AUTOSAR XML (schema 4-3-0)
package /CAN3/ISignalGroup
  17 x i signal group:
    CAN3_SG_B2TM_Info: i-signal=[CAN3_B2TChgSta, CAN3_B2THVCmd, CAN3_B2THVRlySta, CAN3_B2TMCRC, CAN3_B2TMLifeSig, CAN3_B2TPackVol, CAN3_B2TSetModeA, CAN3_B2TSetTemp], system-signal-group=CAN3_SG_B2TM_Info
    CAN3_SG_B2V_BattInfo1: i-signal=[CAN3_B2VBI1BattType, CAN3_B2VBI1RateCap, CAN3_B2VBI1RateHVolt, CAN3_B2VBI1RatePower], system-signal-group=CAN3_SG_B2V_BattInfo1
    CAN3_SG_B2V_CurrentLimit: i-signal=[CAN3_B2VAPlsDischgCurr, CAN3_B2VAvaPlsChgCurr], system-signal-group=CAN3_SG_B2V_CurrentLimit
    CAN3_SG_B2V_Fult1_32960: i-signal=CAN3_B2VHVILFault, system-signal-group=CAN3_SG_B2V_Fult1_32960
    CAN3_SG_B2V_ST1: i-signal=[CAN3_B2VACChgConnSta, CAN3_B2VACChgNegRlySta, CAN3_B2VACChgPosRlySta, CAN3_B2VAux1RlySta, CAN3_B2VAux2RlySta, CAN3_B2VAux3RlySta, CAN3_B2VBMUBalSta, CAN3_B2VBMUHVSta, CAN3_B2VChgMode, CAN3_B2VChgSta, CAN3_B2VCoolingSta, CAN3_B2VDCChgConnSta, CAN3_B2VDCChgN1RlySta, CAN3_B2VDCChgN2RlySta, CAN3_B2VDCChgP1RlySta, CAN3_B2VDCChgP2RlySta, CAN3_B2VHeatNegRelaySta, CAN3_B2VHeatPosRlySta, CAN3_B2VHeatingSta, CAN3_B2VMainNegRlySta, CAN3_B2VMainPosRlySta, CAN3_B2VPChgPosRlySta, CAN3_B2VPChrgConnSta, CAN3_B2VPChrgNegRlySta, CAN3_B2VPrechgRelaySta, CAN3_B2VST1RChrgCy], system-signal-group=CAN3_SG_B2V_ST1
    CAN3_SG_B2V_ST2: i-signal=[CAN3_B2VFaultCode, CAN3_B2VFaultLv, CAN3_B2VPackCurr, CAN3_B2VPackInsideVol, CAN3_B2VRqHVPwrOff, CAN3_B2VSOC, CAN3_B2VSOH, CAN3_B2VST2LifeSig], system-signal-group=CAN3_SG_B2V_ST2
    CAN3_SG_B2V_ST4: i-signal=[CAN3_B2VCellAvgTemp, CAN3_B2VMaxTempCSCSN, CAN3_B2VMaxTempPos, CAN3_B2VMinTempCSCSN, CAN3_B2VMinTempPos, CAN3_B2VPackMaxTemp, CAN3_B2VPackMinTemp], system-signal-group=CAN3_SG_B2V_ST4
    CAN3_SG_B2V_ST5: i-signal=CAN3_B2VCellMinVol, system-signal-group=CAN3_SG_B2V_ST5
    CAN3_SG_EWP1: i-signal=CAN3_EWPPEFault, system-signal-group=CAN3_SG_EWP1
    CAN3_SG_FD3_C100_0: i-signal=[CAN3_V2BACPosRlyFlt, CAN3_V2BACPosRlySta, CAN3_V2BAirPosRlyFlt, CAN3_V2BAirPosRlySta, CAN3_V2BAux1OnOff, CAN3_V2BAux1RlyFlt, CAN3_V2BAux1RlySta, CAN3_V2BAux2OnOff, CAN3_V2BAux2RlyFlt, CAN3_V2BAux2RlySta, CAN3_V2BAux3OnOff, CAN3_V2BAux3RlyFlt, CAN3_V2BAux3RlySta, CAN3_V2BAux4ReyFlt, CAN3_V2BAux4RlySta, CAN3_V2BDCDCPosRlyFlt, CAN3_V2BDCDCPosRlySta, CAN3_V2BHVOnOff, CAN3_V2BLifeSig, CAN3_V2BMainPosRlyFlt, CAN3_V2BMainPosRlySta, CAN3_V2BOilPosRlyFlt, CAN3_V2BOilPosRlySta, CAN3_V2BVehSpd], system-signal-group=CAN3_SG_FD3_C100_0
    CAN3_SG_FD3_C10_0: i-signal=[CAN3_DCDCRlyEn, CAN3_EACRlyEn, CAN3_EHPSRlyEn, CAN3_MCUHVPwrOnOffReq, CAN3_VCULife1], system-signal-group=CAN3_SG_FD3_C10_0
    CAN3_SG_FD3_C10_1: i-signal=[CAN3_VCUMCUCtrlMd, CAN3_VCUMCUDemCS, CAN3_VCUMCUDemHiPosVal, CAN3_VCUMCUDemLoNegVal, CAN3_VCUMCUDemRC, CAN3_VCUMCUDemSpd, CAN3_VCUMCUDemTrq, CAN3_VCUMCUEn, CAN3_VCUMCUFailRst, CAN3_VCUMCUFootBrk, CAN3_VCUMCUGearSta, CAN3_VCUMCUHandBrk], system-signal-group=CAN3_SG_FD3_C10_1
    CAN3_SG_FD3_C200_0: i-signal=[CAN3_ChrgFault, CAN3_ChrgState, CAN3_PowerDownFault, CAN3_PowerDownState, CAN3_PowerUpFault, CAN3_PowerUpState, CAN3_SysPowerMode, CAN3_VCUIGNSta, CAN3_VCUIRCSta, CAN3_VCUPSSSta], system-signal-group=CAN3_SG_FD3_C200_0
    CAN3_SG_FD3_C200_1: i-signal=CAN3_FDC_THCM_EWPPEReq_Cmd, system-signal-group=CAN3_SG_FD3_C200_1
    CAN3_SG_TM_MCUSta1: i-signal=[CAN3_AtvDisChgEnFbk, CAN3_MCUCtrlMdSta, CAN3_MCUIGBTEnFbk, CAN3_MCUMsgSta1LCnt, CAN3_MotorSpd, CAN3_MotorTrq], system-signal-group=CAN3_SG_TM_MCUSta1
    CAN3_SG_TM_MCUSta2: i-signal=[CAN3_MCUFailGrade, CAN3_MCUMsgSta2LCnt, CAN3_MCUTemp, CAN3_MCUTrqLimHi, CAN3_MCUTrqLimLo, CAN3_MotorTemp], system-signal-group=CAN3_SG_TM_MCUSta2
    CAN3_SG_TM_MCUSta3: i-signal=[CAN3_MCUDCCur, CAN3_MCUDCVol, CAN3_MCUFailCode], system-signal-group=CAN3_SG_TM_MCUSta3
package /CAN3/Cluster
  can cluster CAN3: baudrate=500
    can physical channel CAN3: comm-connectors=ConnCAN3
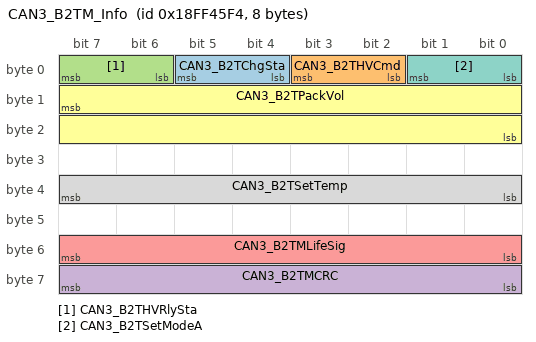
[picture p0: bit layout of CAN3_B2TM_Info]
      frame CAN3_B2TM_Info: id 0x18FF45F4, frame-length=8, can-addressing-mode=EXTENDED, can-fd-frame-support=false, can-frame-rx-behavior=CAN-20, can-frame-tx-behavior=CAN-20
        pdu CAN3_B2TM_Info: length=8, minimum-delay=0.0, transmission-mode-true-timing=cyclic-timing=time-period=1, unused-bit-pattern=0
          mapping CAN3_SG_B2TM_Info: i-signal-group=CAN3_SG_B2TM_Info, start-position=0, transfer-property=PENDING
          signal CAN3_B2TChgSta: start 5, 2 bit, big-endian, i-signal-type=PRIMITIVE, init-value=constant-reference=Init_CAN3_B2TChgSta, base-type=uint8, implementation-data-type=uint8, transfer-property=PENDING
          signal CAN3_B2THVCmd: start 3, 2 bit, big-endian, i-signal-type=PRIMITIVE, init-value=constant-reference=Init_CAN3_B2THVCmd, base-type=uint8, implementation-data-type=uint8, transfer-property=PENDING
          signal CAN3_B2THVRlySta: start 7, 2 bit, big-endian, i-signal-type=PRIMITIVE, init-value=constant-reference=Init_CAN3_B2THVRlySta, base-type=uint8, implementation-data-type=uint8, transfer-property=PENDING
          signal CAN3_B2TMCRC: start 63, 8 bit, big-endian, i-signal-type=PRIMITIVE, init-value=constant-reference=Init_CAN3_B2TMCRC, base-type=uint8, implementation-data-type=uint8, transfer-property=PENDING
          signal CAN3_B2TMLifeSig: start 55, 8 bit, big-endian, i-signal-type=PRIMITIVE, init-value=constant-reference=Init_CAN3_B2TMLifeSig, base-type=uint8, implementation-data-type=uint8, transfer-property=PENDING
          signal CAN3_B2TPackVol: start 15, 16 bit, big-endian, i-signal-type=PRIMITIVE, init-value=constant-reference=Init_CAN3_B2TPackVol, base-type=uint16, implementation-data-type=uint16, transfer-property=PENDING
          signal CAN3_B2TSetModeA: start 1, 2 bit, big-endian, i-signal-type=PRIMITIVE, init-value=constant-reference=Init_CAN3_B2TSetModeA, base-type=uint8, implementation-data-type=uint8, transfer-property=PENDING
          signal CAN3_B2TSetTemp: start 39, 8 bit, big-endian, i-signal-type=PRIMITIVE, init-value=constant-reference=Init_CAN3_B2TSetTemp, base-type=uint8, implementation-data-type=uint8, transfer-property=PENDING
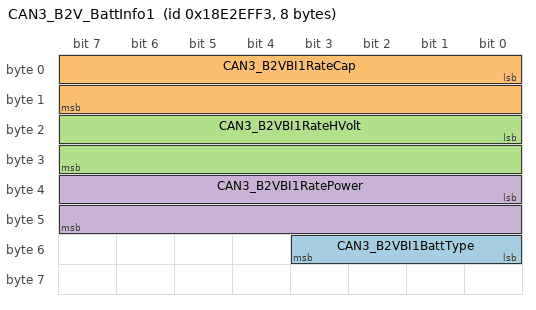
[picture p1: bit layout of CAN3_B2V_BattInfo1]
      frame CAN3_B2V_BattInfo1: id 0x18E2EFF3, frame-length=8, can-addressing-mode=EXTENDED, can-fd-frame-support=false, can-frame-rx-behavior=CAN-20, can-frame-tx-behavior=CAN-20
        pdu CAN3_B2V_BattInfo1: length=8, minimum-delay=0.0, transmission-mode-true-timing=cyclic-timing=time-period=1, unused-bit-pattern=0
          mapping CAN3_SG_B2V_BattInfo1: i-signal-group=CAN3_SG_B2V_BattInfo1, start-position=0, transfer-property=PENDING
          signal CAN3_B2VBI1BattType: start 48, 4 bit, little-endian, i-signal-type=PRIMITIVE, init-value=constant-reference=Init_CAN3_B2VBI1BattType, base-type=uint8, implementation-data-type=uint8, transfer-property=PENDING
          signal CAN3_B2VBI1RateCap: start 0, 16 bit, little-endian, i-signal-type=PRIMITIVE, init-value=constant-reference=Init_CAN3_B2VBI1RateCap, base-type=uint16, implementation-data-type=uint16, transfer-property=PENDING
          signal CAN3_B2VBI1RateHVolt: start 16, 16 bit, little-endian, i-signal-type=PRIMITIVE, init-value=constant-reference=Init_CAN3_B2VBI1RateHVolt, base-type=uint16, implementation-data-type=uint16, transfer-property=PENDING
          signal CAN3_B2VBI1RatePower: start 32, 16 bit, little-endian, i-signal-type=PRIMITIVE, init-value=constant-reference=Init_CAN3_B2VBI1RatePower, base-type=uint16, implementation-data-type=uint16, transfer-property=PENDING
      frame CAN3_B2V_CurrentLimit: id 0x18C4EFF3, frame-length=8, can-addressing-mode=EXTENDED, can-fd-frame-support=false, can-frame-rx-behavior=CAN-20, can-frame-tx-behavior=CAN-20
        pdu CAN3_B2V_CurrentLimit: length=8, minimum-delay=0.0, transmission-mode-true-timing=cyclic-timing=time-period=0.2, unused-bit-pattern=0
          mapping CAN3_SG_B2V_CurrentLimit: i-signal-group=CAN3_SG_B2V_CurrentLimit, start-position=0, transfer-property=PENDING
          signal CAN3_B2VAPlsDischgCurr: start 0, 16 bit, little-endian, i-signal-type=PRIMITIVE, init-value=constant-reference=Init_CAN3_B2VAPlsDischgCurr, base-type=uint16, implementation-data-type=uint16, transfer-property=PENDING
          signal CAN3_B2VAvaPlsChgCurr: start 16, 16 bit, little-endian, i-signal-type=PRIMITIVE, init-value=constant-reference=Init_CAN3_B2VAvaPlsChgCurr, base-type=uint16, implementation-data-type=uint16, transfer-property=PENDING
      frame CAN3_B2V_Fult1_32960: id 0x1881EFF3, frame-length=8, can-addressing-mode=EXTENDED, can-fd-frame-support=false, can-frame-rx-behavior=CAN-20, can-frame-tx-behavior=CAN-20
        pdu CAN3_B2V_Fult1_32960: length=8, minimum-delay=0.0, transmission-mode-true-timing=cyclic-timing=time-period=0.5, unused-bit-pattern=0
          mapping CAN3_SG_B2V_Fult1_32960: i-signal-group=CAN3_SG_B2V_Fult1_32960, start-position=0, transfer-property=PENDING
          signal CAN3_B2VHVILFault: start 26, 1 bit, little-endian, i-signal-type=PRIMITIVE, init-value=constant-reference=Init_CAN3_B2VHVILFault, base-type=uint8, implementation-data-type=uint8, transfer-property=PENDING
      frame CAN3_B2V_ST1: id 0x1883EFF3, frame-length=8, can-addressing-mode=EXTENDED, can-fd-frame-support=false, can-frame-rx-behavior=CAN-20, can-frame-tx-behavior=CAN-20
        pdu CAN3_B2V_ST1: length=8, minimum-delay=0.0, transmission-mode-true-timing=cyclic-timing=time-period=0.1, unused-bit-pattern=0
          mapping CAN3_SG_B2V_ST1: i-signal-group=CAN3_SG_B2V_ST1, start-position=0, transfer-property=PENDING
          signal CAN3_B2VACChgConnSta: start 38, 1 bit, little-endian, i-signal-type=PRIMITIVE, init-value=constant-reference=Init_CAN3_B2VACChgConnSta, base-type=uint8, implementation-data-type=uint8, transfer-property=PENDING
          signal CAN3_B2VACChgNegRlySta: start 24, 2 bit, little-endian, i-signal-type=PRIMITIVE, init-value=constant-reference=Init_CAN3_B2VACChgNegRlySta, base-type=uint8, implementation-data-type=uint8, transfer-property=PENDING
          signal CAN3_B2VACChgPosRlySta: start 22, 2 bit, little-endian, i-signal-type=PRIMITIVE, init-value=constant-reference=Init_CAN3_B2VACChgPosRlySta, base-type=uint8, implementation-data-type=uint8, transfer-property=PENDING
          signal CAN3_B2VAux1RlySta: start 26, 2 bit, little-endian, i-signal-type=PRIMITIVE, init-value=constant-reference=Init_CAN3_B2VAux1RlySta, base-type=uint8, implementation-data-type=uint8, transfer-property=PENDING
          signal CAN3_B2VAux2RlySta: start 28, 2 bit, little-endian, i-signal-type=PRIMITIVE, init-value=constant-reference=Init_CAN3_B2VAux2RlySta, base-type=uint8, implementation-data-type=uint8, transfer-property=PENDING
          signal CAN3_B2VAux3RlySta: start 30, 2 bit, little-endian, i-signal-type=PRIMITIVE, init-value=constant-reference=Init_CAN3_B2VAux3RlySta, base-type=uint8, implementation-data-type=uint8, transfer-property=PENDING
          signal CAN3_B2VBMUBalSta: start 34, 1 bit, little-endian, i-signal-type=PRIMITIVE, init-value=constant-reference=Init_CAN3_B2VBMUBalSta, base-type=uint8, implementation-data-type=uint8, transfer-property=PENDING
          signal CAN3_B2VBMUHVSta: start 32, 2 bit, little-endian, i-signal-type=PRIMITIVE, init-value=constant-reference=Init_CAN3_B2VBMUHVSta, base-type=uint8, implementation-data-type=uint8, transfer-property=PENDING
          signal CAN3_B2VChgMode: start 39, 2 bit, little-endian, i-signal-type=PRIMITIVE, init-value=constant-reference=Init_CAN3_B2VChgMode, base-type=uint8, implementation-data-type=uint8, transfer-property=PENDING
          signal CAN3_B2VChgSta: start 41, 2 bit, little-endian, i-signal-type=PRIMITIVE, init-value=constant-reference=Init_CAN3_B2VChgSta, base-type=uint8, implementation-data-type=uint8, transfer-property=PENDING
          signal CAN3_B2VCoolingSta: start 44, 2 bit, little-endian, i-signal-type=PRIMITIVE, init-value=constant-reference=Init_CAN3_B2VCoolingSta, base-type=uint8, implementation-data-type=uint8, transfer-property=PENDING
          signal CAN3_B2VDCChgConnSta: start 35, 2 bit, little-endian, i-signal-type=PRIMITIVE, init-value=constant-reference=Init_CAN3_B2VDCChgConnSta, base-type=uint8, implementation-data-type=uint8, transfer-property=PENDING
          signal CAN3_B2VDCChgN1RlySta: start 8, 2 bit, little-endian, i-signal-type=PRIMITIVE, init-value=constant-reference=Init_CAN3_B2VDCChgN1RlySta, base-type=uint8, implementation-data-type=uint8, transfer-property=PENDING
          signal CAN3_B2VDCChgN2RlySta: start 12, 2 bit, little-endian, i-signal-type=PRIMITIVE, init-value=constant-reference=Init_CAN3_B2VDCChgN2RlySta, base-type=uint8, implementation-data-type=uint8, transfer-property=PENDING
          signal CAN3_B2VDCChgP1RlySta: start 6, 2 bit, little-endian, i-signal-type=PRIMITIVE, init-value=constant-reference=Init_CAN3_B2VDCChgP1RlySta, base-type=uint8, implementation-data-type=uint8, transfer-property=PENDING
          signal CAN3_B2VDCChgP2RlySta: start 10, 2 bit, little-endian, i-signal-type=PRIMITIVE, init-value=constant-reference=Init_CAN3_B2VDCChgP2RlySta, base-type=uint8, implementation-data-type=uint8, transfer-property=PENDING
          signal CAN3_B2VHeatNegRelaySta: start 16, 2 bit, little-endian, i-signal-type=PRIMITIVE, init-value=constant-reference=Init_CAN3_B2VHeatNegRelaySta, base-type=uint8, implementation-data-type=uint8, transfer-property=PENDING
          signal CAN3_B2VHeatPosRlySta: start 14, 2 bit, little-endian, i-signal-type=PRIMITIVE, init-value=constant-reference=Init_CAN3_B2VHeatPosRlySta, base-type=uint8, implementation-data-type=uint8, transfer-property=PENDING
          signal CAN3_B2VHeatingSta: start 43, 1 bit, little-endian, i-signal-type=PRIMITIVE, init-value=constant-reference=Init_CAN3_B2VHeatingSta, base-type=uint8, implementation-data-type=uint8, transfer-property=PENDING
          signal CAN3_B2VMainNegRlySta: start 2, 2 bit, little-endian, i-signal-type=PRIMITIVE, init-value=constant-reference=Init_CAN3_B2VMainNegRlySta, base-type=uint8, implementation-data-type=uint8, transfer-property=PENDING
          signal CAN3_B2VMainPosRlySta: start 0, 2 bit, little-endian, i-signal-type=PRIMITIVE, init-value=constant-reference=Init_CAN3_B2VMainPosRlySta, base-type=uint8, implementation-data-type=uint8, transfer-property=PENDING
          signal CAN3_B2VPChgPosRlySta: start 18, 2 bit, little-endian, i-signal-type=PRIMITIVE, init-value=constant-reference=Init_CAN3_B2VPChgPosRlySta, base-type=uint8, implementation-data-type=uint8, transfer-property=PENDING
          signal CAN3_B2VPChrgConnSta: start 37, 1 bit, little-endian, i-signal-type=PRIMITIVE, init-value=constant-reference=Init_CAN3_B2VPChrgConnSta, base-type=uint8, implementation-data-type=uint8, transfer-property=PENDING
          signal CAN3_B2VPChrgNegRlySta: start 20, 2 bit, little-endian, i-signal-type=PRIMITIVE, init-value=constant-reference=Init_CAN3_B2VPChrgNegRlySta, base-type=uint8, implementation-data-type=uint8, transfer-property=PENDING
          signal CAN3_B2VPrechgRelaySta: start 4, 2 bit, little-endian, i-signal-type=PRIMITIVE, init-value=constant-reference=Init_CAN3_B2VPrechgRelaySta, base-type=uint8, implementation-data-type=uint8, transfer-property=PENDING
          signal CAN3_B2VST1RChrgCy: start 46, 18 bit, little-endian, i-signal-type=PRIMITIVE, init-value=constant-reference=Init_CAN3_B2VST1RChrgCy, base-type=uint32, implementation-data-type=uint32, transfer-property=PENDING
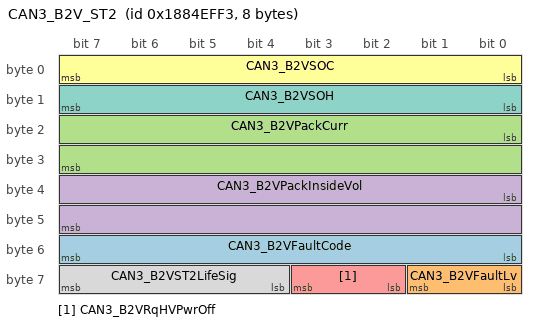
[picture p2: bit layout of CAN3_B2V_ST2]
      frame CAN3_B2V_ST2: id 0x1884EFF3, frame-length=8, can-addressing-mode=EXTENDED, can-fd-frame-support=false, can-frame-rx-behavior=CAN-20, can-frame-tx-behavior=CAN-20
        pdu CAN3_B2V_ST2: length=8, minimum-delay=0.0, transmission-mode-true-timing=cyclic-timing=time-period=0.2, unused-bit-pattern=0
          mapping CAN3_SG_B2V_ST2: i-signal-group=CAN3_SG_B2V_ST2, start-position=0, transfer-property=PENDING
          signal CAN3_B2VFaultCode: start 48, 8 bit, little-endian, i-signal-type=PRIMITIVE, init-value=constant-reference=Init_CAN3_B2VFaultCode, base-type=uint8, implementation-data-type=uint8, transfer-property=PENDING
          signal CAN3_B2VFaultLv: start 56, 2 bit, little-endian, i-signal-type=PRIMITIVE, init-value=constant-reference=Init_CAN3_B2VFaultLv, base-type=uint8, implementation-data-type=uint8, transfer-property=PENDING
          signal CAN3_B2VPackCurr: start 16, 16 bit, little-endian, i-signal-type=PRIMITIVE, init-value=constant-reference=Init_CAN3_B2VPackCurr, base-type=uint16, implementation-data-type=uint16, transfer-property=PENDING
          signal CAN3_B2VPackInsideVol: start 32, 16 bit, little-endian, i-signal-type=PRIMITIVE, init-value=constant-reference=Init_CAN3_B2VPackInsideVol, base-type=uint16, implementation-data-type=uint16, transfer-property=PENDING
          signal CAN3_B2VRqHVPwrOff: start 58, 2 bit, little-endian, i-signal-type=PRIMITIVE, init-value=constant-reference=Init_CAN3_B2VRqHVPwrOff, base-type=uint8, implementation-data-type=uint8, transfer-property=PENDING
          signal CAN3_B2VSOC: start 0, 8 bit, little-endian, i-signal-type=PRIMITIVE, init-value=constant-reference=Init_CAN3_B2VSOC, base-type=uint8, implementation-data-type=uint8, transfer-property=PENDING
          signal CAN3_B2VSOH: start 8, 8 bit, little-endian, i-signal-type=PRIMITIVE, init-value=constant-reference=Init_CAN3_B2VSOH, base-type=uint8, implementation-data-type=uint8, transfer-property=PENDING
          signal CAN3_B2VST2LifeSig: start 60, 4 bit, little-endian, i-signal-type=PRIMITIVE, init-value=constant-reference=Init_CAN3_B2VST2LifeSig, base-type=uint8, implementation-data-type=uint8, transfer-property=PENDING
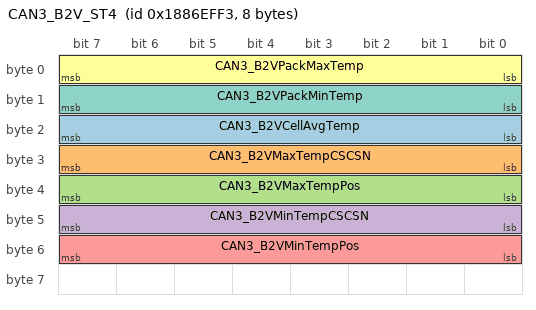
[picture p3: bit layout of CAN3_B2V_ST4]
      frame CAN3_B2V_ST4: id 0x1886EFF3, frame-length=8, can-addressing-mode=EXTENDED, can-fd-frame-support=false, can-frame-rx-behavior=CAN-20, can-frame-tx-behavior=CAN-20
        pdu CAN3_B2V_ST4: length=8, minimum-delay=0.0, transmission-mode-true-timing=cyclic-timing=time-period=0.5, unused-bit-pattern=0
          mapping CAN3_SG_B2V_ST4: i-signal-group=CAN3_SG_B2V_ST4, start-position=0, transfer-property=PENDING
          signal CAN3_B2VCellAvgTemp: start 16, 8 bit, little-endian, i-signal-type=PRIMITIVE, init-value=constant-reference=Init_CAN3_B2VCellAvgTemp, base-type=uint8, implementation-data-type=uint8, transfer-property=PENDING
          signal CAN3_B2VMaxTempCSCSN: start 24, 8 bit, little-endian, i-signal-type=PRIMITIVE, init-value=constant-reference=Init_CAN3_B2VMaxTempCSCSN, base-type=uint8, implementation-data-type=uint8, transfer-property=PENDING
          signal CAN3_B2VMaxTempPos: start 32, 8 bit, little-endian, i-signal-type=PRIMITIVE, init-value=constant-reference=Init_CAN3_B2VMaxTempPos, base-type=uint8, implementation-data-type=uint8, transfer-property=PENDING
          signal CAN3_B2VMinTempCSCSN: start 40, 8 bit, little-endian, i-signal-type=PRIMITIVE, init-value=constant-reference=Init_CAN3_B2VMinTempCSCSN, base-type=uint8, implementation-data-type=uint8, transfer-property=PENDING
          signal CAN3_B2VMinTempPos: start 48, 8 bit, little-endian, i-signal-type=PRIMITIVE, init-value=constant-reference=Init_CAN3_B2VMinTempPos, base-type=uint8, implementation-data-type=uint8, transfer-property=PENDING
          signal CAN3_B2VPackMaxTemp: start 0, 8 bit, little-endian, i-signal-type=PRIMITIVE, init-value=constant-reference=Init_CAN3_B2VPackMaxTemp, base-type=uint8, implementation-data-type=uint8, transfer-property=PENDING
          signal CAN3_B2VPackMinTemp: start 8, 8 bit, little-endian, i-signal-type=PRIMITIVE, init-value=constant-reference=Init_CAN3_B2VPackMinTemp, base-type=uint8, implementation-data-type=uint8, transfer-property=PENDING
      frame CAN3_B2V_ST5: id 0x1887EFF3, frame-length=8, can-addressing-mode=EXTENDED, can-fd-frame-support=false, can-frame-rx-behavior=CAN-20, can-frame-tx-behavior=CAN-20
        pdu CAN3_B2V_ST5: length=8, minimum-delay=0.0, transmission-mode-true-timing=cyclic-timing=time-period=0.5, unused-bit-pattern=0
          mapping CAN3_SG_B2V_ST5: i-signal-group=CAN3_SG_B2V_ST5, start-position=0, transfer-property=PENDING
          signal CAN3_B2VCellMinVol: start 16, 16 bit, little-endian, i-signal-type=PRIMITIVE, init-value=constant-reference=Init_CAN3_B2VCellMinVol, base-type=uint16, implementation-data-type=uint16, transfer-property=PENDING
      frame CAN3_DiagFuncReqFT: id 0x7D0, frame-length=8, can-addressing-mode=STANDARD, can-fd-frame-support=false, can-frame-rx-behavior=CAN-20, can-frame-tx-behavior=CAN-20
        n pdu CAN3_DiagFuncReqFT: length=8
      frame CAN3_DiagPhyReqToEWP1: id 0x18DA87F9, frame-length=8, can-addressing-mode=EXTENDED, can-fd-frame-support=false, can-frame-rx-behavior=CAN-20, can-frame-tx-behavior=CAN-20
        n pdu CAN3_DiagPhyReqToEWP1: length=8
      frame CAN3_DiagPhysReqToBMS: id 0x18DAF4F9, frame-length=8, can-addressing-mode=EXTENDED, can-fd-frame-support=false, can-frame-rx-behavior=CAN-20, can-frame-tx-behavior=CAN-20
        n pdu CAN3_DiagPhysReqToBMS: length=8
      frame CAN3_DiagPhysReqToMCU: id 0x18DA05F9, frame-length=8, can-addressing-mode=EXTENDED, can-fd-frame-support=false, can-frame-rx-behavior=CAN-20, can-frame-tx-behavior=CAN-20
        n pdu CAN3_DiagPhysReqToMCU: length=8
      frame CAN3_DiagRespFromBMS: id 0x18DAF9F4, frame-length=8, can-addressing-mode=EXTENDED, can-fd-frame-support=false, can-frame-rx-behavior=CAN-20, can-frame-tx-behavior=CAN-20
        n pdu CAN3_DiagRespFromBMS: length=8
      frame CAN3_DiagRespFromEWP1: id 0x18DAF987, frame-length=8, can-addressing-mode=EXTENDED, can-fd-frame-support=false, can-frame-rx-behavior=CAN-20, can-frame-tx-behavior=CAN-20
        n pdu CAN3_DiagRespFromEWP1: length=8
      frame CAN3_DiagRespFromMCU: id 0x18DAF905, frame-length=8, can-addressing-mode=EXTENDED, can-fd-frame-support=false, can-frame-rx-behavior=CAN-20, can-frame-tx-behavior=CAN-20
        n pdu CAN3_DiagRespFromMCU: length=8
      frame CAN3_EWP1: id 0x18FFEE39, frame-length=8, can-addressing-mode=EXTENDED, can-fd-frame-support=false, can-frame-rx-behavior=CAN-20, can-frame-tx-behavior=CAN-20
        pdu CAN3_EWP1: length=8, minimum-delay=0.0, transmission-mode-true-timing=cyclic-timing=time-period=0.2, unused-bit-pattern=0
          mapping CAN3_SG_EWP1: i-signal-group=CAN3_SG_EWP1, start-position=0, transfer-property=PENDING
          signal CAN3_EWPPEFault: start 24, 8 bit, little-endian, i-signal-type=PRIMITIVE, init-value=constant-reference=Init_CAN3_EWPPEFault, base-type=uint8, implementation-data-type=uint8, transfer-property=PENDING
      frame CAN3_FD3_C100_0: id 0x1802F3EF, frame-length=8, can-addressing-mode=EXTENDED, can-fd-frame-support=false, can-frame-rx-behavior=CAN-20, can-frame-tx-behavior=CAN-20
        pdu CAN3_FD3_C100_0: length=8, minimum-delay=0.0, transmission-mode-true-timing=cyclic-timing=time-period=0.1, unused-bit-pattern=0
          mapping CAN3_SG_FD3_C100_0: i-signal-group=CAN3_SG_FD3_C100_0, start-position=0, transfer-property=PENDING
          signal CAN3_V2BACPosRlyFlt: start 30, 2 bit, little-endian, i-signal-type=PRIMITIVE, init-value=constant-reference=Init_CAN3_V2BACPosRlyFlt, base-type=uint8, implementation-data-type=uint8, transfer-property=PENDING
          signal CAN3_V2BACPosRlySta: start 28, 2 bit, little-endian, i-signal-type=PRIMITIVE, init-value=constant-reference=Init_CAN3_V2BACPosRlySta, base-type=uint8, implementation-data-type=uint8, transfer-property=PENDING
          signal CAN3_V2BAirPosRlyFlt: start 34, 2 bit, little-endian, i-signal-type=PRIMITIVE, init-value=constant-reference=Init_CAN3_V2BAirPosRlyFlt, base-type=uint8, implementation-data-type=uint8, transfer-property=PENDING
          signal CAN3_V2BAirPosRlySta: start 32, 2 bit, little-endian, i-signal-type=PRIMITIVE, init-value=constant-reference=Init_CAN3_V2BAirPosRlySta, base-type=uint8, implementation-data-type=uint8, transfer-property=PENDING
          signal CAN3_V2BAux1OnOff: start 10, 2 bit, little-endian, i-signal-type=PRIMITIVE, init-value=constant-reference=Init_CAN3_V2BAux1OnOff, base-type=uint8, implementation-data-type=uint8, transfer-property=PENDING
          signal CAN3_V2BAux1RlyFlt: start 46, 2 bit, little-endian, i-signal-type=PRIMITIVE, init-value=constant-reference=Init_CAN3_V2BAux1RlyFlt, base-type=uint8, implementation-data-type=uint8, transfer-property=PENDING
          signal CAN3_V2BAux1RlySta: start 44, 2 bit, little-endian, i-signal-type=PRIMITIVE, init-value=constant-reference=Init_CAN3_V2BAux1RlySta, base-type=uint8, implementation-data-type=uint8, transfer-property=PENDING
          signal CAN3_V2BAux2OnOff: start 12, 2 bit, little-endian, i-signal-type=PRIMITIVE, init-value=constant-reference=Init_CAN3_V2BAux2OnOff, base-type=uint8, implementation-data-type=uint8, transfer-property=PENDING
          signal CAN3_V2BAux2RlyFlt: start 50, 2 bit, little-endian, i-signal-type=PRIMITIVE, init-value=constant-reference=Init_CAN3_V2BAux2RlyFlt, base-type=uint8, implementation-data-type=uint8, transfer-property=PENDING
          signal CAN3_V2BAux2RlySta: start 48, 2 bit, little-endian, i-signal-type=PRIMITIVE, init-value=constant-reference=Init_CAN3_V2BAux2RlySta, base-type=uint8, implementation-data-type=uint8, transfer-property=PENDING
          signal CAN3_V2BAux3OnOff: start 14, 2 bit, little-endian, i-signal-type=PRIMITIVE, init-value=constant-reference=Init_CAN3_V2BAux3OnOff, base-type=uint8, implementation-data-type=uint8, transfer-property=PENDING
          signal CAN3_V2BAux3RlyFlt: start 54, 2 bit, little-endian, i-signal-type=PRIMITIVE, init-value=constant-reference=Init_CAN3_V2BAux3RlyFlt, base-type=uint8, implementation-data-type=uint8, transfer-property=PENDING
          signal CAN3_V2BAux3RlySta: start 52, 2 bit, little-endian, i-signal-type=PRIMITIVE, init-value=constant-reference=Init_CAN3_V2BAux3RlySta, base-type=uint8, implementation-data-type=uint8, transfer-property=PENDING
          signal CAN3_V2BAux4ReyFlt: start 58, 2 bit, little-endian, i-signal-type=PRIMITIVE, init-value=constant-reference=Init_CAN3_V2BAux4ReyFlt, base-type=uint8, implementation-data-type=uint8, transfer-property=PENDING
          signal CAN3_V2BAux4RlySta: start 56, 2 bit, little-endian, i-signal-type=PRIMITIVE, init-value=constant-reference=Init_CAN3_V2BAux4RlySta, base-type=uint8, implementation-data-type=uint8, transfer-property=PENDING
          signal CAN3_V2BDCDCPosRlyFlt: start 42, 2 bit, little-endian, i-signal-type=PRIMITIVE, init-value=constant-reference=Init_CAN3_V2BDCDCPosRlyFlt, base-type=uint8, implementation-data-type=uint8, transfer-property=PENDING
          signal CAN3_V2BDCDCPosRlySta: start 40, 2 bit, little-endian, i-signal-type=PRIMITIVE, init-value=constant-reference=Init_CAN3_V2BDCDCPosRlySta, base-type=uint8, implementation-data-type=uint8, transfer-property=PENDING
          signal CAN3_V2BHVOnOff: start 8, 2 bit, little-endian, i-signal-type=PRIMITIVE, init-value=constant-reference=Init_CAN3_V2BHVOnOff, base-type=uint8, implementation-data-type=uint8, transfer-property=PENDING
          signal CAN3_V2BLifeSig: start 0, 8 bit, little-endian, i-signal-type=PRIMITIVE, init-value=constant-reference=Init_CAN3_V2BLifeSig, base-type=uint8, implementation-data-type=uint8, transfer-property=PENDING
          signal CAN3_V2BMainPosRlyFlt: start 26, 2 bit, little-endian, i-signal-type=PRIMITIVE, init-value=constant-reference=Init_CAN3_V2BMainPosRlyFlt, base-type=uint8, implementation-data-type=uint8, transfer-property=PENDING
          signal CAN3_V2BMainPosRlySta: start 24, 2 bit, little-endian, i-signal-type=PRIMITIVE, init-value=constant-reference=Init_CAN3_V2BMainPosRlySta, base-type=uint8, implementation-data-type=uint8, transfer-property=PENDING
          signal CAN3_V2BOilPosRlyFlt: start 38, 2 bit, little-endian, i-signal-type=PRIMITIVE, init-value=constant-reference=Init_CAN3_V2BOilPosRlyFlt, base-type=uint8, implementation-data-type=uint8, transfer-property=PENDING
          signal CAN3_V2BOilPosRlySta: start 36, 2 bit, little-endian, i-signal-type=PRIMITIVE, init-value=constant-reference=Init_CAN3_V2BOilPosRlySta, base-type=uint8, implementation-data-type=uint8, transfer-property=PENDING
          signal CAN3_V2BVehSpd: start 16, 8 bit, little-endian, i-signal-type=PRIMITIVE, init-value=constant-reference=Init_CAN3_V2BVehSpd, base-type=uint8, implementation-data-type=uint8, transfer-property=PENDING
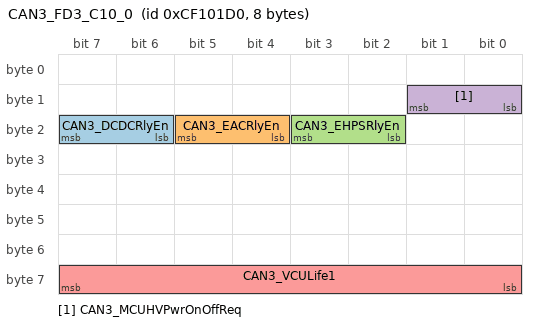
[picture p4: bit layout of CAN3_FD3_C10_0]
      frame CAN3_FD3_C10_0: id 0xCF101D0, frame-length=8, can-addressing-mode=EXTENDED, can-fd-frame-support=false, can-frame-rx-behavior=CAN-20, can-frame-tx-behavior=CAN-20
        pdu CAN3_FD3_C10_0: length=8, minimum-delay=0.0, transmission-mode-true-timing=cyclic-timing=time-period=0.01, unused-bit-pattern=0
          mapping CAN3_SG_FD3_C10_0: i-signal-group=CAN3_SG_FD3_C10_0, start-position=0, transfer-property=PENDING
          signal CAN3_DCDCRlyEn: start 22, 2 bit, little-endian, i-signal-type=PRIMITIVE, init-value=constant-reference=Init_CAN3_DCDCRlyEn, base-type=uint8, implementation-data-type=uint8, transfer-property=PENDING
          signal CAN3_EACRlyEn: start 20, 2 bit, little-endian, i-signal-type=PRIMITIVE, init-value=constant-reference=Init_CAN3_EACRlyEn, base-type=uint8, implementation-data-type=uint8, transfer-property=PENDING
          signal CAN3_EHPSRlyEn: start 18, 2 bit, little-endian, i-signal-type=PRIMITIVE, init-value=constant-reference=Init_CAN3_EHPSRlyEn, base-type=uint8, implementation-data-type=uint8, transfer-property=PENDING
          signal CAN3_MCUHVPwrOnOffReq: start 8, 2 bit, little-endian, i-signal-type=PRIMITIVE, init-value=constant-reference=Init_CAN3_MCUHVPwrOnOffReq, base-type=uint8, implementation-data-type=uint8, transfer-property=PENDING
          signal CAN3_VCULife1: start 56, 8 bit, little-endian, i-signal-type=PRIMITIVE, init-value=constant-reference=Init_CAN3_VCULife1, base-type=uint8, implementation-data-type=uint8, transfer-property=PENDING
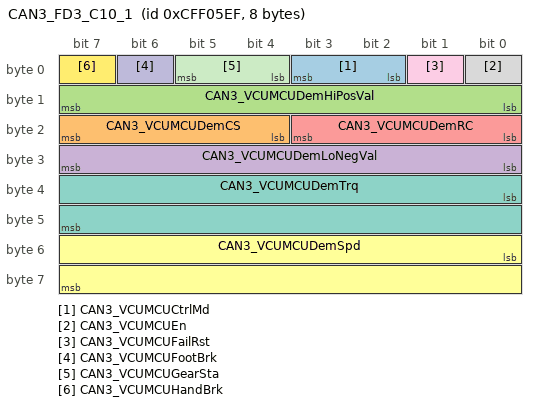
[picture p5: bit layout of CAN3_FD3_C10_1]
      frame CAN3_FD3_C10_1: id 0xCFF05EF, frame-length=8, can-addressing-mode=EXTENDED, can-fd-frame-support=false, can-frame-rx-behavior=CAN-20, can-frame-tx-behavior=CAN-20
        pdu CAN3_FD3_C10_1: length=8, minimum-delay=0.0, transmission-mode-true-timing=cyclic-timing=time-period=0.01, unused-bit-pattern=0
          mapping CAN3_SG_FD3_C10_1: i-signal-group=CAN3_SG_FD3_C10_1, start-position=0, transfer-property=PENDING
          signal CAN3_VCUMCUCtrlMd: start 2, 2 bit, little-endian, i-signal-type=PRIMITIVE, init-value=constant-reference=Init_CAN3_VCUMCUCtrlMd, base-type=uint8, implementation-data-type=uint8, transfer-property=PENDING
          signal CAN3_VCUMCUDemCS: start 20, 4 bit, little-endian, i-signal-type=PRIMITIVE, init-value=constant-reference=Init_CAN3_VCUMCUDemCS, base-type=uint8, implementation-data-type=uint8, transfer-property=PENDING
          signal CAN3_VCUMCUDemHiPosVal: start 8, 8 bit, little-endian, i-signal-type=PRIMITIVE, init-value=constant-reference=Init_CAN3_VCUMCUDemHiPosVal, base-type=uint8, implementation-data-type=uint8, transfer-property=PENDING
          signal CAN3_VCUMCUDemLoNegVal: start 24, 8 bit, little-endian, i-signal-type=PRIMITIVE, init-value=constant-reference=Init_CAN3_VCUMCUDemLoNegVal, base-type=uint8, implementation-data-type=uint8, transfer-property=PENDING
          signal CAN3_VCUMCUDemRC: start 16, 4 bit, little-endian, i-signal-type=PRIMITIVE, init-value=constant-reference=Init_CAN3_VCUMCUDemRC, base-type=uint8, implementation-data-type=uint8, transfer-property=PENDING
          signal CAN3_VCUMCUDemSpd: start 48, 16 bit, little-endian, i-signal-type=PRIMITIVE, init-value=constant-reference=Init_CAN3_VCUMCUDemSpd, base-type=uint16, implementation-data-type=uint16, transfer-property=PENDING
          signal CAN3_VCUMCUDemTrq: start 32, 16 bit, little-endian, i-signal-type=PRIMITIVE, init-value=constant-reference=Init_CAN3_VCUMCUDemTrq, base-type=uint16, implementation-data-type=uint16, transfer-property=PENDING
          signal CAN3_VCUMCUEn: start 0, 1 bit, little-endian, i-signal-type=PRIMITIVE, init-value=constant-reference=Init_CAN3_VCUMCUEn, base-type=uint8, implementation-data-type=uint8, transfer-property=PENDING
          signal CAN3_VCUMCUFailRst: start 1, 1 bit, little-endian, i-signal-type=PRIMITIVE, init-value=constant-reference=Init_CAN3_VCUMCUFailRst, base-type=uint8, implementation-data-type=uint8, transfer-property=PENDING
          signal CAN3_VCUMCUFootBrk: start 6, 1 bit, little-endian, i-signal-type=PRIMITIVE, init-value=constant-reference=Init_CAN3_VCUMCUFootBrk, base-type=uint8, implementation-data-type=uint8, transfer-property=PENDING
          signal CAN3_VCUMCUGearSta: start 4, 2 bit, little-endian, i-signal-type=PRIMITIVE, init-value=constant-reference=Init_CAN3_VCUMCUGearSta, base-type=uint8, implementation-data-type=uint8, transfer-property=PENDING
          signal CAN3_VCUMCUHandBrk: start 7, 1 bit, little-endian, i-signal-type=PRIMITIVE, init-value=constant-reference=Init_CAN3_VCUMCUHandBrk, base-type=uint8, implementation-data-type=uint8, transfer-property=PENDING
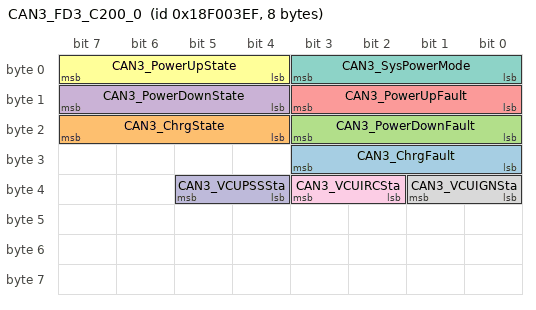
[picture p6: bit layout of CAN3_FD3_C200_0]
      frame CAN3_FD3_C200_0: id 0x18F003EF, frame-length=8, can-addressing-mode=EXTENDED, can-fd-frame-support=false, can-frame-rx-behavior=CAN-20, can-frame-tx-behavior=CAN-20
        pdu CAN3_FD3_C200_0: length=8, minimum-delay=0.0, transmission-mode-true-timing=cyclic-timing=time-period=0.2, unused-bit-pattern=0
          mapping CAN3_SG_FD3_C200_0: i-signal-group=CAN3_SG_FD3_C200_0, start-position=0, transfer-property=PENDING
          signal CAN3_ChrgFault: start 24, 4 bit, little-endian, i-signal-type=PRIMITIVE, init-value=constant-reference=Init_CAN3_ChrgFault, base-type=uint8, implementation-data-type=uint8, transfer-property=PENDING
          signal CAN3_ChrgState: start 20, 4 bit, little-endian, i-signal-type=PRIMITIVE, init-value=constant-reference=Init_CAN3_ChrgState, base-type=uint8, implementation-data-type=uint8, transfer-property=PENDING
          signal CAN3_PowerDownFault: start 16, 4 bit, little-endian, i-signal-type=PRIMITIVE, init-value=constant-reference=Init_CAN3_PowerDownFault, base-type=uint8, implementation-data-type=uint8, transfer-property=PENDING
          signal CAN3_PowerDownState: start 12, 4 bit, little-endian, i-signal-type=PRIMITIVE, init-value=constant-reference=Init_CAN3_PowerDownState, base-type=uint8, implementation-data-type=uint8, transfer-property=PENDING
          signal CAN3_PowerUpFault: start 8, 4 bit, little-endian, i-signal-type=PRIMITIVE, init-value=constant-reference=Init_CAN3_PowerUpFault, base-type=uint8, implementation-data-type=uint8, transfer-property=PENDING
          signal CAN3_PowerUpState: start 4, 4 bit, little-endian, i-signal-type=PRIMITIVE, init-value=constant-reference=Init_CAN3_PowerUpState, base-type=uint8, implementation-data-type=uint8, transfer-property=PENDING
          signal CAN3_SysPowerMode: start 0, 4 bit, little-endian, i-signal-type=PRIMITIVE, init-value=constant-reference=Init_CAN3_SysPowerMode, base-type=uint8, implementation-data-type=uint8, transfer-property=PENDING
          signal CAN3_VCUIGNSta: start 32, 2 bit, little-endian, i-signal-type=PRIMITIVE, init-value=constant-reference=Init_CAN3_VCUIGNSta, base-type=uint8, implementation-data-type=uint8, transfer-property=PENDING
          signal CAN3_VCUIRCSta: start 34, 2 bit, little-endian, i-signal-type=PRIMITIVE, init-value=constant-reference=Init_CAN3_VCUIRCSta, base-type=uint8, implementation-data-type=uint8, transfer-property=PENDING
          signal CAN3_VCUPSSSta: start 36, 2 bit, little-endian, i-signal-type=PRIMITIVE, init-value=constant-reference=Init_CAN3_VCUPSSSta, base-type=uint8, implementation-data-type=uint8, transfer-property=PENDING
      frame CAN3_FD3_C200_1: id 0x18F001EF, frame-length=8, can-addressing-mode=EXTENDED, can-fd-frame-support=false, can-frame-rx-behavior=CAN-20, can-frame-tx-behavior=CAN-20
        pdu CAN3_FD3_C200_1: length=8, minimum-delay=0.0, transmission-mode-true-timing=cyclic-timing=time-period=0.2, unused-bit-pattern=0
          mapping CAN3_SG_FD3_C200_1: i-signal-group=CAN3_SG_FD3_C200_1, start-position=0, transfer-property=PENDING
          signal CAN3_FDC_THCM_EWPPEReq_Cmd: start 0, 8 bit, little-endian, i-signal-type=PRIMITIVE, init-value=constant-reference=Init_CAN3_FDC_THCM_EWPPEReq_Cmd, base-type=uint8, implementation-data-type=uint8, transfer-property=PENDING
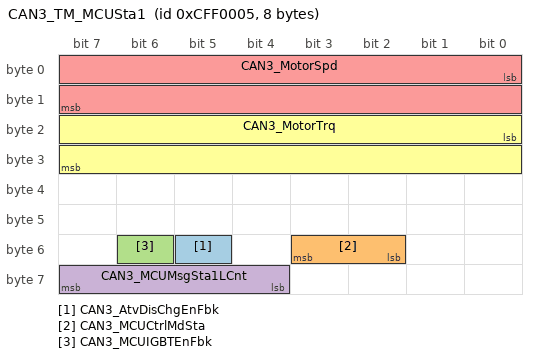
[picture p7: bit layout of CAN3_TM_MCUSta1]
      frame CAN3_TM_MCUSta1: id 0xCFF0005, frame-length=8, can-addressing-mode=EXTENDED, can-fd-frame-support=false, can-frame-rx-behavior=CAN-20, can-frame-tx-behavior=CAN-20
        pdu CAN3_TM_MCUSta1: length=8, minimum-delay=0.0, transmission-mode-true-timing=cyclic-timing=time-period=0.01, unused-bit-pattern=0
          mapping CAN3_SG_TM_MCUSta1: i-signal-group=CAN3_SG_TM_MCUSta1, start-position=0, transfer-property=PENDING
          signal CAN3_AtvDisChgEnFbk: start 53, 1 bit, little-endian, i-signal-type=PRIMITIVE, init-value=constant-reference=Init_CAN3_AtvDisChgEnFbk, base-type=uint8, implementation-data-type=uint8, transfer-property=PENDING
          signal CAN3_MCUCtrlMdSta: start 50, 2 bit, little-endian, i-signal-type=PRIMITIVE, init-value=constant-reference=Init_CAN3_MCUCtrlMdSta, base-type=uint8, implementation-data-type=uint8, transfer-property=PENDING
          signal CAN3_MCUIGBTEnFbk: start 54, 1 bit, little-endian, i-signal-type=PRIMITIVE, init-value=constant-reference=Init_CAN3_MCUIGBTEnFbk, base-type=uint8, implementation-data-type=uint8, transfer-property=PENDING
          signal CAN3_MCUMsgSta1LCnt: start 60, 4 bit, little-endian, i-signal-type=PRIMITIVE, init-value=constant-reference=Init_CAN3_MCUMsgSta1LCnt, base-type=uint8, implementation-data-type=uint8, transfer-property=PENDING
          signal CAN3_MotorSpd: start 0, 16 bit, little-endian, i-signal-type=PRIMITIVE, init-value=constant-reference=Init_CAN3_MotorSpd, base-type=uint16, implementation-data-type=uint16, transfer-property=PENDING
          signal CAN3_MotorTrq: start 16, 16 bit, little-endian, i-signal-type=PRIMITIVE, init-value=constant-reference=Init_CAN3_MotorTrq, base-type=uint16, implementation-data-type=uint16, transfer-property=PENDING
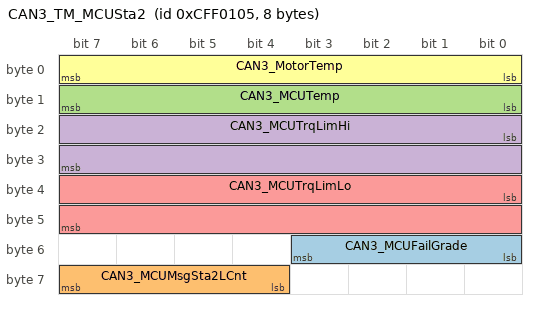
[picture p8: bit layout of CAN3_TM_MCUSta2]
      frame CAN3_TM_MCUSta2: id 0xCFF0105, frame-length=8, can-addressing-mode=EXTENDED, can-fd-frame-support=false, can-frame-rx-behavior=CAN-20, can-frame-tx-behavior=CAN-20
        pdu CAN3_TM_MCUSta2: length=8, minimum-delay=0.0, transmission-mode-true-timing=cyclic-timing=time-period=0.05, unused-bit-pattern=0
          mapping CAN3_SG_TM_MCUSta2: i-signal-group=CAN3_SG_TM_MCUSta2, start-position=0, transfer-property=PENDING
          signal CAN3_MCUFailGrade: start 48, 4 bit, little-endian, i-signal-type=PRIMITIVE, init-value=constant-reference=Init_CAN3_MCUFailGrade, base-type=uint8, implementation-data-type=uint8, transfer-property=PENDING
          signal CAN3_MCUMsgSta2LCnt: start 60, 4 bit, little-endian, i-signal-type=PRIMITIVE, init-value=constant-reference=Init_CAN3_MCUMsgSta2LCnt, base-type=uint8, implementation-data-type=uint8, transfer-property=PENDING
          signal CAN3_MCUTemp: start 8, 8 bit, little-endian, i-signal-type=PRIMITIVE, init-value=constant-reference=Init_CAN3_MCUTemp, base-type=uint8, implementation-data-type=uint8, transfer-property=PENDING
          signal CAN3_MCUTrqLimHi: start 16, 16 bit, little-endian, i-signal-type=PRIMITIVE, init-value=constant-reference=Init_CAN3_MCUTrqLimHi, base-type=uint16, implementation-data-type=uint16, transfer-property=PENDING
          signal CAN3_MCUTrqLimLo: start 32, 16 bit, little-endian, i-signal-type=PRIMITIVE, init-value=constant-reference=Init_CAN3_MCUTrqLimLo, base-type=uint16, implementation-data-type=uint16, transfer-property=PENDING
          signal CAN3_MotorTemp: start 0, 8 bit, little-endian, i-signal-type=PRIMITIVE, init-value=constant-reference=Init_CAN3_MotorTemp, base-type=uint8, implementation-data-type=uint8, transfer-property=PENDING
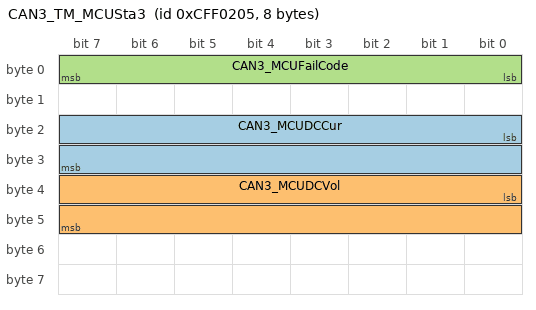
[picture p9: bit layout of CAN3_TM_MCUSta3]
      frame CAN3_TM_MCUSta3: id 0xCFF0205, frame-length=8, can-addressing-mode=EXTENDED, can-fd-frame-support=false, can-frame-rx-behavior=CAN-20, can-frame-tx-behavior=CAN-20
        pdu CAN3_TM_MCUSta3: length=8, minimum-delay=0.0, transmission-mode-true-timing=cyclic-timing=time-period=0.1, unused-bit-pattern=0
          mapping CAN3_SG_TM_MCUSta3: i-signal-group=CAN3_SG_TM_MCUSta3, start-position=0, transfer-property=PENDING
          signal CAN3_MCUDCCur: start 16, 16 bit, little-endian, i-signal-type=PRIMITIVE, init-value=constant-reference=Init_CAN3_MCUDCCur, base-type=uint16, implementation-data-type=uint16, transfer-property=PENDING
          signal CAN3_MCUDCVol: start 32, 16 bit, little-endian, i-signal-type=PRIMITIVE, init-value=constant-reference=Init_CAN3_MCUDCVol, base-type=uint16, implementation-data-type=uint16, transfer-property=PENDING
          signal CAN3_MCUFailCode: start 0, 8 bit, little-endian, i-signal-type=PRIMITIVE, init-value=constant-reference=Init_CAN3_MCUFailCode, base-type=uint8, implementation-data-type=uint8, transfer-property=PENDING
      frame CAN3_NMm_FUSION_TX: id 0x500, frame-length=8, can-addressing-mode=STANDARD, can-fd-frame-support=false, can-frame-rx-behavior=CAN-20, can-frame-tx-behavior=CAN-20
        nm pdu CAN3_NMm_FUSION_TX: length=8, unused-bit-pattern=0
      frame CAN3_NMm_FUSION_RX: id 0x500, frame-length=8, can-addressing-mode=STANDARD, can-fd-frame-support=false, can-frame-rx-behavior=CAN-20, can-frame-tx-behavior=CAN-20
        nm pdu CAN3_NMm_FUSION_RX: length=8, unused-bit-pattern=0
package /CAN3/ConstantSpecification
  142 x constant specification:
    Init_CAN3_B2TChgSta: value-spec=0
    Init_CAN3_B2THVCmd: value-spec=0
    Init_CAN3_B2THVRlySta: value-spec=0
    Init_CAN3_B2TMCRC: value-spec=0
    Init_CAN3_B2TMLifeSig: value-spec=0
    Init_CAN3_B2TPackVol: value-spec=0
    Init_CAN3_B2TSetModeA: value-spec=0
    Init_CAN3_B2TSetTemp: value-spec=0
    Init_CAN3_B2VBI1BattType: value-spec=0
    Init_CAN3_B2VBI1RateCap: value-spec=0
    Init_CAN3_B2VBI1RateHVolt: value-spec=0
    Init_CAN3_B2VBI1RatePower: value-spec=0
    Init_CAN3_B2VAPlsDischgCurr: value-spec=0
    Init_CAN3_B2VAvaPlsChgCurr: value-spec=0
    Init_CAN3_B2VHVILFault: value-spec=0
    Init_CAN3_B2VACChgConnSta: value-spec=0
    Init_CAN3_B2VACChgNegRlySta: value-spec=0
    Init_CAN3_B2VACChgPosRlySta: value-spec=0
    Init_CAN3_B2VAux{1..3}RlySta: value-spec=0
    Init_CAN3_B2VBMUBalSta: value-spec=0
    Init_CAN3_B2VBMUHVSta: value-spec=0
    Init_CAN3_B2VChgMode: value-spec=0
    Init_CAN3_B2VChgSta: value-spec=0
    Init_CAN3_B2VCoolingSta: value-spec=0
    Init_CAN3_B2VDCChgConnSta: value-spec=0
    Init_CAN3_B2VDCChgN1RlySta: value-spec=0
    Init_CAN3_B2VDCChgN2RlySta: value-spec=0
    Init_CAN3_B2VDCChgP1RlySta: value-spec=0
    Init_CAN3_B2VDCChgP2RlySta: value-spec=0
    Init_CAN3_B2VHeatNegRelaySta: value-spec=0
    Init_CAN3_B2VHeatPosRlySta: value-spec=0
    Init_CAN3_B2VHeatingSta: value-spec=0
    Init_CAN3_B2VMainNegRlySta: value-spec=0
    Init_CAN3_B2VMainPosRlySta: value-spec=0
    Init_CAN3_B2VPChgPosRlySta: value-spec=0
    Init_CAN3_B2VPChrgConnSta: value-spec=0
    Init_CAN3_B2VPChrgNegRlySta: value-spec=0
    Init_CAN3_B2VPrechgRelaySta: value-spec=0
    Init_CAN3_B2VST1RChrgCy: value-spec=0
    Init_CAN3_B2VFaultCode: value-spec=0
    Init_CAN3_B2VFaultLv: value-spec=0
    Init_CAN3_B2VPackCurr: value-spec=0
    Init_CAN3_B2VPackInsideVol: value-spec=0
    Init_CAN3_B2VRqHVPwrOff: value-spec=0
    Init_CAN3_B2VSOC: value-spec=0
    Init_CAN3_B2VSOH: value-spec=0
    Init_CAN3_B2VST2LifeSig: value-spec=0
    Init_CAN3_B2VCellAvgTemp: value-spec=0
    Init_CAN3_B2VMaxTempCSCSN: value-spec=0
    Init_CAN3_B2VMaxTempPos: value-spec=0
    Init_CAN3_B2VMinTempCSCSN: value-spec=0
    Init_CAN3_B2VMinTempPos: value-spec=0
    Init_CAN3_B2VPackMaxTemp: value-spec=0
    Init_CAN3_B2VPackMinTemp: value-spec=0
    Init_CAN3_B2VCellMinVol: value-spec=0
    Init_CAN3_EWPPEFault: value-spec=0
    Init_CAN3_V2BACPosRlyFlt: value-spec=0
    Init_CAN3_V2BACPosRlySta: value-spec=0
    Init_CAN3_V2BAirPosRlyFlt: value-spec=0
    Init_CAN3_V2BAirPosRlySta: value-spec=0
    Init_CAN3_V2BAux1OnOff: value-spec=0
    Init_CAN3_V2BAux1RlyFlt: value-spec=0
    Init_CAN3_V2BAux1RlySta: value-spec=0
    Init_CAN3_V2BAux2OnOff: value-spec=0
    Init_CAN3_V2BAux2RlyFlt: value-spec=0
    Init_CAN3_V2BAux2RlySta: value-spec=0
    Init_CAN3_V2BAux3OnOff: value-spec=0
    Init_CAN3_V2BAux3RlyFlt: value-spec=0
    Init_CAN3_V2BAux3RlySta: value-spec=0
    Init_CAN3_V2BAux4ReyFlt: value-spec=0
    Init_CAN3_V2BAux4RlySta: value-spec=0
    Init_CAN3_V2BDCDCPosRlyFlt: value-spec=0
    Init_CAN3_V2BDCDCPosRlySta: value-spec=0
    Init_CAN3_V2BHVOnOff: value-spec=0
    Init_CAN3_V2BLifeSig: value-spec=0
    Init_CAN3_V2BMainPosRlyFlt: value-spec=0
    Init_CAN3_V2BMainPosRlySta: value-spec=0
    Init_CAN3_V2BOilPosRlyFlt: value-spec=0
    Init_CAN3_V2BOilPosRlySta: value-spec=0
    Init_CAN3_V2BVehSpd: value-spec=0
    Init_CAN3_DCDCRlyEn: value-spec=0
    Init_CAN3_EACRlyEn: value-spec=0
    Init_CAN3_EHPSRlyEn: value-spec=0
    Init_CAN3_MCUHVPwrOnOffReq: value-spec=0
    Init_CAN3_VCULife1: value-spec=0
    Init_CAN3_VCUMCUCtrlMd: value-spec=0
    Init_CAN3_VCUMCUDemCS: value-spec=0
    Init_CAN3_VCUMCUDemHiPosVal: value-spec=0
    Init_CAN3_VCUMCUDemLoNegVal: value-spec=0
    Init_CAN3_VCUMCUDemRC: value-spec=0
    Init_CAN3_VCUMCUDemSpd: value-spec=0
    Init_CAN3_VCUMCUDemTrq: value-spec=0
    Init_CAN3_VCUMCUEn: value-spec=0
    Init_CAN3_VCUMCUFailRst: value-spec=0
    Init_CAN3_VCUMCUFootBrk: value-spec=0
    Init_CAN3_VCUMCUGearSta: value-spec=0
    Init_CAN3_VCUMCUHandBrk: value-spec=0
    Init_CAN3_ChrgFault: value-spec=0
    Init_CAN3_ChrgState: value-spec=0
    Init_CAN3_PowerDownFault: value-spec=0
    Init_CAN3_PowerDownState: value-spec=0
    Init_CAN3_PowerUpFault: value-spec=0
    Init_CAN3_PowerUpState: value-spec=0
    Init_CAN3_SysPowerMode: value-spec=0
    Init_CAN3_VCUIGNSta: value-spec=0
    Init_CAN3_VCUIRCSta: value-spec=0
    Init_CAN3_VCUPSSSta: value-spec=0
    Init_CAN3_FDC_THCM_EWPPEReq_Cmd: value-spec=0
    Init_CAN3_AtvDisChgEnFbk: value-spec=0
    Init_CAN3_MCUCtrlMdSta: value-spec=2
    Init_CAN3_MCUIGBTEnFbk: value-spec=0
    Init_CAN3_MCUMsgSta1LCnt: value-spec=0
    Init_CAN3_MotorSpd: value-spec=15000
    Init_CAN3_MotorTrq: value-spec=5000
    Init_CAN3_MCUFailGrade: value-spec=0
    Init_CAN3_MCUMsgSta2LCnt: value-spec=0
    Init_CAN3_MCUTemp: value-spec=40
    Init_CAN3_MCUTrqLimHi: value-spec=0
    Init_CAN3_MCUTrqLimLo: value-spec=5000
    Init_CAN3_MotorTemp: value-spec=40
    Init_CAN3_MCUDCCur: value-spec=1000
    Init_CAN3_MCUDCVol: value-spec=0
    Init_CAN3_MCUFailCode: value-spec=0
    Init_CAN3_SG_B2TM_Info: value-spec=fields=[Init_CAN3_B2TChgSta, Init_CAN3_B2THVCmd, Init_CAN3_B2THVRlySta, Init_CAN3_B2TMCRC, Init_CAN3_B2TMLifeSig, Init_CAN3_B2TPackVol, Init_CAN3_B2TSetModeA, Init_CAN3_B2TSetTemp]
    Init_CAN3_SG_B2V_BattInfo1: value-spec=fields=[Init_CAN3_B2VBI1BattType, Init_CAN3_B2VBI1RateCap, Init_CAN3_B2VBI1RateHVolt, Init_CAN3_B2VBI1RatePower]
    Init_CAN3_SG_B2V_CurrentLimit: value-spec=fields=[Init_CAN3_B2VAPlsDischgCurr, Init_CAN3_B2VAvaPlsChgCurr]
    Init_CAN3_SG_B2V_Fult1_32960: value-spec=fields=constant-reference=Init_CAN3_B2VHVILFault
    Init_CAN3_SG_B2V_ST1: value-spec=fields=[Init_CAN3_B2VACChgConnSta, Init_CAN3_B2VACChgNegRlySta, Init_CAN3_B2VACChgPosRlySta, Init_CAN3_B2VAux1RlySta, Init_CAN3_B2VAux2RlySta, Init_CAN3_B2VAux3RlySta, Init_CAN3_B2VBMUBalSta, Init_CAN3_B2VBMUHVSta, Init_CAN3_B2VChgMode, Init_CAN3_B2VChgSta, Init_CAN3_B2VCoolingSta, Init_CAN3_B2VDCChgConnSta, Init_CAN3_B2VDCChgN1RlySta, Init_CAN3_B2VDCChgN2RlySta, Init_CAN3_B2VDCChgP1RlySta, Init_CAN3_B2VDCChgP2RlySta, Init_CAN3_B2VHeatNegRelaySta, Init_CAN3_B2VHeatPosRlySta, Init_CAN3_B2VHeatingSta, Init_CAN3_B2VMainNegRlySta, Init_CAN3_B2VMainPosRlySta, Init_CAN3_B2VPChgPosRlySta, Init_CAN3_B2VPChrgConnSta, Init_CAN3_B2VPChrgNegRlySta, Init_CAN3_B2VPrechgRelaySta, Init_CAN3_B2VST1RChrgCy]
    Init_CAN3_SG_B2V_ST2: value-spec=fields=[Init_CAN3_B2VFaultCode, Init_CAN3_B2VFaultLv, Init_CAN3_B2VPackCurr, Init_CAN3_B2VPackInsideVol, Init_CAN3_B2VRqHVPwrOff, Init_CAN3_B2VSOC, Init_CAN3_B2VSOH, Init_CAN3_B2VST2LifeSig]
    Init_CAN3_SG_B2V_ST4: value-spec=fields=[Init_CAN3_B2VCellAvgTemp, Init_CAN3_B2VMaxTempCSCSN, Init_CAN3_B2VMaxTempPos, Init_CAN3_B2VMinTempCSCSN, Init_CAN3_B2VMinTempPos, Init_CAN3_B2VPackMaxTemp, Init_CAN3_B2VPackMinTemp]
    Init_CAN3_SG_B2V_ST5: value-spec=fields=constant-reference=Init_CAN3_B2VCellMinVol
    Init_CAN3_SG_EWP1: value-spec=fields=constant-reference=Init_CAN3_EWPPEFault
    Init_CAN3_SG_FD3_C100_0: value-spec=fields=[Init_CAN3_V2BACPosRlyFlt, Init_CAN3_V2BACPosRlySta, Init_CAN3_V2BAirPosRlyFlt, Init_CAN3_V2BAirPosRlySta, Init_CAN3_V2BAux1OnOff, Init_CAN3_V2BAux1RlyFlt, Init_CAN3_V2BAux1RlySta, Init_CAN3_V2BAux2OnOff, Init_CAN3_V2BAux2RlyFlt, Init_CAN3_V2BAux2RlySta, Init_CAN3_V2BAux3OnOff, Init_CAN3_V2BAux3RlyFlt, Init_CAN3_V2BAux3RlySta, Init_CAN3_V2BAux4ReyFlt, Init_CAN3_V2BAux4RlySta, Init_CAN3_V2BDCDCPosRlyFlt, Init_CAN3_V2BDCDCPosRlySta, Init_CAN3_V2BHVOnOff, Init_CAN3_V2BLifeSig, Init_CAN3_V2BMainPosRlyFlt, Init_CAN3_V2BMainPosRlySta, Init_CAN3_V2BOilPosRlyFlt, Init_CAN3_V2BOilPosRlySta, Init_CAN3_V2BVehSpd]
    Init_CAN3_SG_FD3_C10_0: value-spec=fields=[Init_CAN3_DCDCRlyEn, Init_CAN3_EACRlyEn, Init_CAN3_EHPSRlyEn, Init_CAN3_MCUHVPwrOnOffReq, Init_CAN3_VCULife1]
    Init_CAN3_SG_FD3_C10_1: value-spec=fields=[Init_CAN3_VCUMCUCtrlMd, Init_CAN3_VCUMCUDemCS, Init_CAN3_VCUMCUDemHiPosVal, Init_CAN3_VCUMCUDemLoNegVal, Init_CAN3_VCUMCUDemRC, Init_CAN3_VCUMCUDemSpd, Init_CAN3_VCUMCUDemTrq, Init_CAN3_VCUMCUEn, Init_CAN3_VCUMCUFailRst, Init_CAN3_VCUMCUFootBrk, Init_CAN3_VCUMCUGearSta, Init_CAN3_VCUMCUHandBrk]
    Init_CAN3_SG_FD3_C200_0: value-spec=fields=[Init_CAN3_ChrgFault, Init_CAN3_ChrgState, Init_CAN3_PowerDownFault, Init_CAN3_PowerDownState, Init_CAN3_PowerUpFault, Init_CAN3_PowerUpState, Init_CAN3_SysPowerMode, Init_CAN3_VCUIGNSta, Init_CAN3_VCUIRCSta, Init_CAN3_VCUPSSSta]
    Init_CAN3_SG_FD3_C200_1: value-spec=fields=constant-reference=Init_CAN3_FDC_THCM_EWPPEReq_Cmd
    Init_CAN3_SG_TM_MCUSta1: value-spec=fields=[Init_CAN3_AtvDisChgEnFbk, Init_CAN3_MCUCtrlMdSta, Init_CAN3_MCUIGBTEnFbk, Init_CAN3_MCUMsgSta1LCnt, Init_CAN3_MotorSpd, Init_CAN3_MotorTrq]
    Init_CAN3_SG_TM_MCUSta2: value-spec=fields=[Init_CAN3_MCUFailGrade, Init_CAN3_MCUMsgSta2LCnt, Init_CAN3_MCUTemp, Init_CAN3_MCUTrqLimHi, Init_CAN3_MCUTrqLimLo, Init_CAN3_MotorTemp]
    Init_CAN3_SG_TM_MCUSta3: value-spec=fields=[Init_CAN3_MCUDCCur, Init_CAN3_MCUDCVol, Init_CAN3_MCUFailCode]
package /CAN3/ImplementationDataTypes
  17 x impl type, all with category=STRUCTURE:
    DT_CAN3_SG_B2TM_Info
      8 x element, all with category=TYPE_REFERENCE:
        CAN3_B2TChgSta: implementation-data-type=uint8
        CAN3_B2THVCmd: implementation-data-type=uint8
        CAN3_B2THVRlySta: implementation-data-type=uint8
        CAN3_B2TMCRC: implementation-data-type=uint8
        CAN3_B2TMLifeSig: implementation-data-type=uint8
        CAN3_B2TPackVol: implementation-data-type=uint16
        CAN3_B2TSetModeA: implementation-data-type=uint8
        CAN3_B2TSetTemp: implementation-data-type=uint8
    DT_CAN3_SG_B2V_BattInfo1
      4 x element, all with category=TYPE_REFERENCE:
        CAN3_B2VBI1BattType: implementation-data-type=uint8
        CAN3_B2VBI1RateCap: implementation-data-type=uint16
        CAN3_B2VBI1RateHVolt: implementation-data-type=uint16
        CAN3_B2VBI1RatePower: implementation-data-type=uint16
    DT_CAN3_SG_B2V_CurrentLimit
      element CAN3_B2VAPlsDischgCurr: implementation-data-type=uint16
      element CAN3_B2VAvaPlsChgCurr: implementation-data-type=uint16
    DT_CAN3_SG_B2V_Fult1_32960
      element CAN3_B2VHVILFault: implementation-data-type=uint8
    DT_CAN3_SG_B2V_ST1
      26 x element, all with category=TYPE_REFERENCE:
        CAN3_B2VACChgConnSta: implementation-data-type=uint8
        CAN3_B2VACChgNegRlySta: implementation-data-type=uint8
        CAN3_B2VACChgPosRlySta: implementation-data-type=uint8
        CAN3_B2VAux{1..3}RlySta: implementation-data-type=uint8
        CAN3_B2VBMUBalSta: implementation-data-type=uint8
        CAN3_B2VBMUHVSta: implementation-data-type=uint8
        CAN3_B2VChgMode: implementation-data-type=uint8
        CAN3_B2VChgSta: implementation-data-type=uint8
        CAN3_B2VCoolingSta: implementation-data-type=uint8
        CAN3_B2VDCChgConnSta: implementation-data-type=uint8
        CAN3_B2VDCChgN1RlySta: implementation-data-type=uint8
        CAN3_B2VDCChgN2RlySta: implementation-data-type=uint8
        CAN3_B2VDCChgP1RlySta: implementation-data-type=uint8
        CAN3_B2VDCChgP2RlySta: implementation-data-type=uint8
        CAN3_B2VHeatNegRelaySta: implementation-data-type=uint8
        CAN3_B2VHeatPosRlySta: implementation-data-type=uint8
        CAN3_B2VHeatingSta: implementation-data-type=uint8
        CAN3_B2VMainNegRlySta: implementation-data-type=uint8
        CAN3_B2VMainPosRlySta: implementation-data-type=uint8
        CAN3_B2VPChgPosRlySta: implementation-data-type=uint8
        CAN3_B2VPChrgConnSta: implementation-data-type=uint8
        CAN3_B2VPChrgNegRlySta: implementation-data-type=uint8
        CAN3_B2VPrechgRelaySta: implementation-data-type=uint8
        CAN3_B2VST1RChrgCy: implementation-data-type=uint32
    DT_CAN3_SG_B2V_ST2
      8 x element, all with category=TYPE_REFERENCE:
        CAN3_B2VFaultCode: implementation-data-type=uint8
        CAN3_B2VFaultLv: implementation-data-type=uint8
        CAN3_B2VPackCurr: implementation-data-type=uint16
        CAN3_B2VPackInsideVol: implementation-data-type=uint16
        CAN3_B2VRqHVPwrOff: implementation-data-type=uint8
        CAN3_B2VSOC: implementation-data-type=uint8
        CAN3_B2VSOH: implementation-data-type=uint8
        CAN3_B2VST2LifeSig: implementation-data-type=uint8
    DT_CAN3_SG_B2V_ST4
      7 x element, all with category=TYPE_REFERENCE, implementation-data-type=uint8:
        CAN3_B2VCellAvgTemp
        CAN3_B2VMaxTempCSCSN
        CAN3_B2VMaxTempPos
        CAN3_B2VMinTempCSCSN
        CAN3_B2VMinTempPos
        CAN3_B2VPackMaxTemp
        CAN3_B2VPackMinTemp
    DT_CAN3_SG_B2V_ST5
      element CAN3_B2VCellMinVol: implementation-data-type=uint16
    DT_CAN3_SG_EWP1
      element CAN3_EWPPEFault: implementation-data-type=uint8
    DT_CAN3_SG_FD3_C100_0
      24 x element, all with category=TYPE_REFERENCE, implementation-data-type=uint8:
        CAN3_V2BACPosRlyFlt
        CAN3_V2BACPosRlySta
        CAN3_V2BAirPosRlyFlt
        CAN3_V2BAirPosRlySta
        CAN3_V2BAux1OnOff
        CAN3_V2BAux1RlyFlt
        CAN3_V2BAux1RlySta
        CAN3_V2BAux2OnOff
        CAN3_V2BAux2RlyFlt
        CAN3_V2BAux2RlySta
        CAN3_V2BAux3OnOff
        CAN3_V2BAux3RlyFlt
        CAN3_V2BAux3RlySta
        CAN3_V2BAux4ReyFlt
        CAN3_V2BAux4RlySta
        CAN3_V2BDCDCPosRlyFlt
        CAN3_V2BDCDCPosRlySta
        CAN3_V2BHVOnOff
        CAN3_V2BLifeSig
        CAN3_V2BMainPosRlyFlt
        CAN3_V2BMainPosRlySta
        CAN3_V2BOilPosRlyFlt
        CAN3_V2BOilPosRlySta
        CAN3_V2BVehSpd
    DT_CAN3_SG_FD3_C10_0
      5 x element, all with category=TYPE_REFERENCE, implementation-data-type=uint8:
        CAN3_DCDCRlyEn
        CAN3_EACRlyEn
        CAN3_EHPSRlyEn
        CAN3_MCUHVPwrOnOffReq
        CAN3_VCULife1
    DT_CAN3_SG_FD3_C10_1
      12 x element, all with category=TYPE_REFERENCE:
        CAN3_VCUMCUCtrlMd: implementation-data-type=uint8
        CAN3_VCUMCUDemCS: implementation-data-type=uint8
        CAN3_VCUMCUDemHiPosVal: implementation-data-type=uint8
        CAN3_VCUMCUDemLoNegVal: implementation-data-type=uint8
        CAN3_VCUMCUDemRC: implementation-data-type=uint8
        CAN3_VCUMCUDemSpd: implementation-data-type=uint16
        CAN3_VCUMCUDemTrq: implementation-data-type=uint16
        CAN3_VCUMCUEn: implementation-data-type=uint8
        CAN3_VCUMCUFailRst: implementation-data-type=uint8
        CAN3_VCUMCUFootBrk: implementation-data-type=uint8
        CAN3_VCUMCUGearSta: implementation-data-type=uint8
        CAN3_VCUMCUHandBrk: implementation-data-type=uint8
    DT_CAN3_SG_FD3_C200_0
      10 x element, all with category=TYPE_REFERENCE, implementation-data-type=uint8:
        CAN3_ChrgFault
        CAN3_ChrgState
        CAN3_PowerDownFault
        CAN3_PowerDownState
        CAN3_PowerUpFault
        CAN3_PowerUpState
        CAN3_SysPowerMode
        CAN3_VCUIGNSta
        CAN3_VCUIRCSta
        CAN3_VCUPSSSta
    DT_CAN3_SG_FD3_C200_1
      element CAN3_FDC_THCM_EWPPEReq_Cmd: implementation-data-type=uint8
    DT_CAN3_SG_TM_MCUSta1
      6 x element, all with category=TYPE_REFERENCE:
        CAN3_AtvDisChgEnFbk: implementation-data-type=uint8
        CAN3_MCUCtrlMdSta: implementation-data-type=uint8
        CAN3_MCUIGBTEnFbk: implementation-data-type=uint8
        CAN3_MCUMsgSta1LCnt: implementation-data-type=uint8
        CAN3_MotorSpd: implementation-data-type=uint16
        CAN3_MotorTrq: implementation-data-type=uint16
    DT_CAN3_SG_TM_MCUSta2
      6 x element, all with category=TYPE_REFERENCE:
        CAN3_MCUFailGrade: implementation-data-type=uint8
        CAN3_MCUMsgSta2LCnt: implementation-data-type=uint8
        CAN3_MCUTemp: implementation-data-type=uint8
        CAN3_MCUTrqLimHi: implementation-data-type=uint16
        CAN3_MCUTrqLimLo: implementation-data-type=uint16
        CAN3_MotorTemp: implementation-data-type=uint8
    DT_CAN3_SG_TM_MCUSta3
      element CAN3_MCUDCCur: implementation-data-type=uint16
      element CAN3_MCUDCVol: implementation-data-type=uint16
      element CAN3_MCUFailCode: implementation-data-type=uint8
